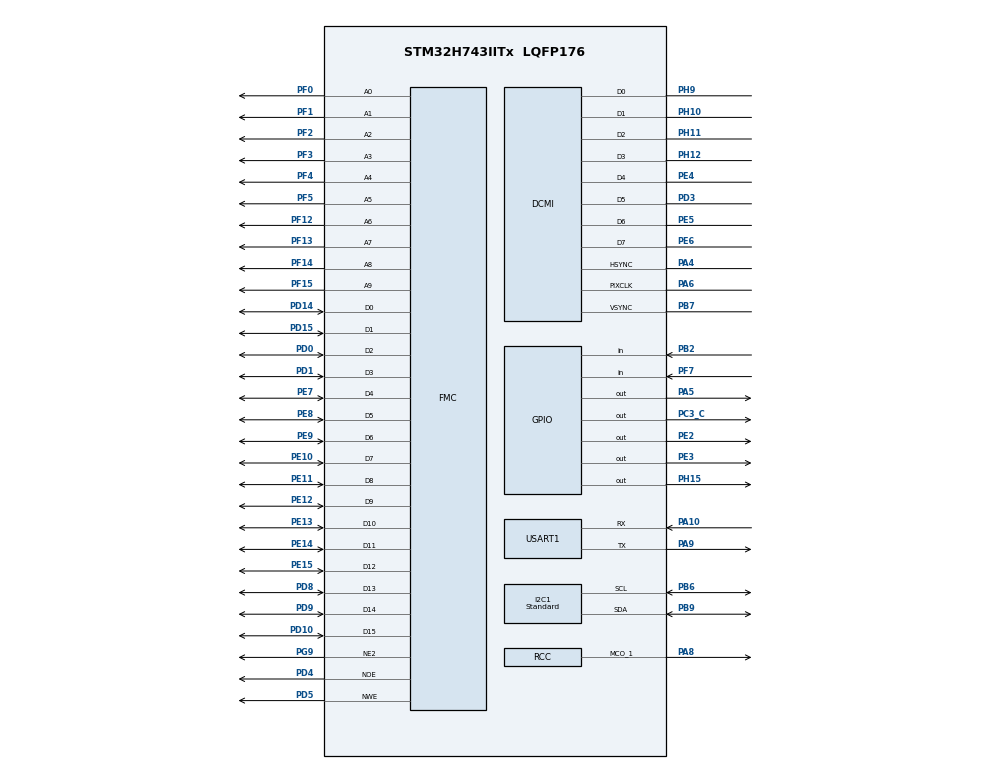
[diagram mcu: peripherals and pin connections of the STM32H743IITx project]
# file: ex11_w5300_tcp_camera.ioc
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DCMI.JPEGMode=DCMI_JPEG_DISABLE
DCMI.PCKPolarity=DCMI_PCKPOLARITY_RISING
Dma.DCMI.0.Direction=DMA_PERIPH_TO_MEMORY
Dma.DCMI.0.EventEnable=DISABLE
Dma.DCMI.0.FIFOMode=DMA_FIFOMODE_ENABLE
Dma.DCMI.0.FIFOThreshold=DMA_FIFO_THRESHOLD_FULL
Dma.DCMI.0.Instance=DMA2_Stream1
Dma.DCMI.0.MemBurst=DMA_MBURST_SINGLE
Dma.DCMI.0.MemDataAlignment=DMA_MDATAALIGN_WORD
Dma.DCMI.0.MemInc=DMA_MINC_ENABLE
Dma.DCMI.0.Mode=DMA_CIRCULAR
Dma.DCMI.0.PeriphBurst=DMA_PBURST_SINGLE
Dma.DCMI.0.PeriphDataAlignment=DMA_PDATAALIGN_WORD
Dma.DCMI.0.PeriphInc=DMA_PINC_DISABLE
Dma.DCMI.0.Polarity=HAL_DMAMUX_REQ_GEN_RISING
Dma.DCMI.0.Priority=DMA_PRIORITY_VERY_HIGH
Dma.DCMI.0.RequestNumber=1
Dma.DCMI.0.SignalID=NONE
Dma.DCMI.0.SyncEnable=DISABLE
Dma.DCMI.0.SyncPolarity=HAL_DMAMUX_SYNC_NO_EVENT
Dma.DCMI.0.SyncRequestNumber=1
Dma.DCMI.0.SyncSignalID=NONE
Dma.Request0=DCMI
FMC.ExtendedMode1=FMC_EXTENDED_MODE_ENABLE
FMC.WriteFifo1=FMC_WRITE_FIFO_DISABLE
FMC.WriteOperation1=FMC_WRITE_OPERATION_ENABLE
I2C1.I2C_Speed_Mode=I2C_Standard
I2C1.Timing=0x307075B1
Mcu.Family=STM32H7
Mcu.Name=STM32H743IITx
Mcu.Package=LQFP176
NVIC.DCMI_IRQn=true\:0\:0\:false\:false\:true\:true\:true\:true
NVIC.DMA2_Stream1_IRQn=true\:0\:0\:false\:false\:true\:false\:true\:true
NVIC.PriorityGroup=NVIC_PRIORITYGROUP_4
PA10.Mode=Asynchronous
PA10.Signal=USART1_RX
PA13\ (JTMS/SWDIO).Mode=Serial_Wire
PA13\ (JTMS/SWDIO).Signal=DEBUG_JTMS-SWDIO
PA14\ (JTCK/SWCLK).Mode=Serial_Wire
PA14\ (JTCK/SWCLK).Signal=DEBUG_JTCK-SWCLK
PA4.Mode=Slave_8_bits_External_Synchro
PA4.Signal=DCMI_HSYNC
PA5.Signal=GPIO_Output
PA6.Mode=Slave_8_bits_External_Synchro
PA6.Signal=DCMI_PIXCLK
PA8.Mode=Clock-out-1
PA8.Signal=RCC_MCO_1
PA9.Mode=Asynchronous
PA9.Signal=USART1_TX
PB10.Signal=I2C2_SCL
PB11.Signal=I2C2_SDA
PB2.Signal=GPIO_Input
PB6.Mode=I2C
PB6.Signal=I2C1_SCL
PB7.Mode=Slave_8_bits_External_Synchro
PB7.Signal=DCMI_VSYNC
PB9.Mode=I2C
PB9.Signal=I2C1_SDA
PC3_C.Signal=GPIO_Output
PD0.Signal=FMC_D2_DA2
PD1.Signal=FMC_D3_DA3
PD10.Signal=FMC_D15_DA15
PD14.Signal=FMC_D0_DA0
PD15.Signal=FMC_D1_DA1
PD3.Mode=Slave_8_bits_External_Synchro
PD3.Signal=DCMI_D5
PD4.Signal=FMC_NOE
PD5.Signal=FMC_NWE
PD7.Signal=FMC_NE1
PD8.Signal=FMC_D13_DA13
PD9.Signal=FMC_D14_DA14
PE10.Signal=FMC_D7_DA7
PE11.Signal=FMC_D8_DA8
PE12.Signal=FMC_D9_DA9
PE13.Signal=FMC_D10_DA10
PE14.Signal=FMC_D11_DA11
PE15.Signal=FMC_D12_DA12
PE2.Signal=GPIO_Output
PE3.Signal=GPIO_Output
PE4.Mode=Slave_8_bits_External_Synchro
PE4.Signal=DCMI_D4
PE5.Mode=Slave_8_bits_External_Synchro
PE5.Signal=DCMI_D6
PE6.Mode=Slave_8_bits_External_Synchro
PE6.Signal=DCMI_D7
PE7.Signal=FMC_D4_DA4
PE8.Signal=FMC_D5_DA5
PE9.Signal=FMC_D6_DA6
PF0.Signal=FMC_A0
PF1.Signal=FMC_A1
PF12.Signal=FMC_A6
PF13.Signal=FMC_A7
PF14.Signal=FMC_A8
PF15.Signal=FMC_A9
PF2.Signal=FMC_A2
PF3.Signal=FMC_A3
PF4.Signal=FMC_A4
PF5.Signal=FMC_A5
PF7.Signal=GPIO_Input
PG10.Signal=FMC_NE3
PG9.Mode=NorPsramChipSelect2_1
PG9.Signal=FMC_NE2
PH10.Mode=Slave_8_bits_External_Synchro
PH10.Signal=DCMI_D1
PH11.Mode=Slave_8_bits_External_Synchro
PH11.Signal=DCMI_D2
PH12.Mode=Slave_8_bits_External_Synchro
PH12.Signal=DCMI_D3
PH15.Signal=GPIO_Output
PH9.Mode=Slave_8_bits_External_Synchro
PH9.Signal=DCMI_D0
ProjectManager.HeapSize=0x200
ProjectManager.StackSize=0x400
ProjectManager.TargetToolchain=STM32CubeIDE
RCC.ADCFreq_Value=129000000
RCC.APB1Freq_Value=120000000
RCC.APB2Freq_Value=120000000
RCC.APB3Freq_Value=120000000
RCC.APB4Freq_Value=120000000
RCC.CortexFreq_Value=480000000
RCC.D1PPRE=RCC_APB3_DIV2
RCC.D2PPRE1=RCC_APB1_DIV2
RCC.D2PPRE2=RCC_APB2_DIV2
RCC.D3PPRE=RCC_APB4_DIV2
RCC.DIVM1=4
RCC.DIVN1=60
RCC.HCLKFreq_Value=240000000
RCC.HPRE=RCC_HCLK_DIV2
RCC.RCC_MCODiv1=RCC_MCODIV_4
RCC.SYSCLKFreq_VALUE=480000000
RCC.SYSCLKSource=RCC_SYSCLKSOURCE_PLLCLK
RCC.USBFreq_Value=480000000
SH.FMC_A0.0=FMC_A0,10b-a1
SH.FMC_A1.0=FMC_A1,10b-a1
SH.FMC_A2.0=FMC_A2,10b-a1
SH.FMC_A3.0=FMC_A3,10b-a1
SH.FMC_A4.0=FMC_A4,10b-a1
SH.FMC_A5.0=FMC_A5,10b-a1
SH.FMC_A6.0=FMC_A6,10b-a1
SH.FMC_A7.0=FMC_A7,10b-a1
SH.FMC_A8.0=FMC_A8,10b-a1
SH.FMC_A9.0=FMC_A9,10b-a1
SH.FMC_D0_DA0.0=FMC_D0,16b-d1
SH.FMC_D10_DA10.0=FMC_D10,16b-d1
SH.FMC_D11_DA11.0=FMC_D11,16b-d1
SH.FMC_D12_DA12.0=FMC_D12,16b-d1
SH.FMC_D13_DA13.0=FMC_D13,16b-d1
SH.FMC_D14_DA14.0=FMC_D14,16b-d1
SH.FMC_D15_DA15.0=FMC_D15,16b-d1
SH.FMC_D1_DA1.0=FMC_D1,16b-d1
SH.FMC_D2_DA2.0=FMC_D2,16b-d1
SH.FMC_D3_DA3.0=FMC_D3,16b-d1
SH.FMC_D4_DA4.0=FMC_D4,16b-d1
SH.FMC_D5_DA5.0=FMC_D5,16b-d1
SH.FMC_D6_DA6.0=FMC_D6,16b-d1
SH.FMC_D7_DA7.0=FMC_D7,16b-d1
SH.FMC_D8_DA8.0=FMC_D8,16b-d1
SH.FMC_D9_DA9.0=FMC_D9,16b-d1
SH.FMC_NOE.0=FMC_NOE,Sram1
SH.FMC_NWE.0=FMC_NWE,Sram1
USART1.VirtualMode-Asynchronous=VM_ASYNC
board=custom

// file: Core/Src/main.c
/* USER CODE BEGIN Header */
/**
  ******************************************************************************
  * @file           : main.c
  * @brief          : Main program body
  ******************************************************************************
  * @attention
  *
  * Copyright (c) 2023 STMicroelectronics.
  * All rights reserved.
  *
  * This software is licensed under terms that can be found in the LICENSE file
  * in the root directory of this software component.
  * If no LICENSE file comes with this software, it is provided AS-IS.
  *
  ******************************************************************************
  */
/* USER CODE END Header */
#include "main.h"

DCMI_HandleTypeDef hdcmi;
DMA_HandleTypeDef hdma_dcmi;

I2C_HandleTypeDef hi2c1;

UART_HandleTypeDef huart1;

SRAM_HandleTypeDef hsram1;

void SystemClock_Config(void);
static void MX_GPIO_Init(void);
static void MX_DMA_Init(void);
static void MX_DCMI_Init(void);
static void MX_FMC_Init(void);
static void MX_USART1_UART_Init(void);
static void MX_I2C1_Init(void);
/* USER CODE BEGIN PFP */

#define _CAM_SOCK_NUM		0
#define _CAM_ETHER_PORT		3000

#define _CMD_CAM_START		0xFE
#define _CMD_CAM_STOP		0xFD
#define _CMD_CAM_SIZE		0xFC
#define _CMD_LED			0xF0
#define _CMD_CAM_LINE		0xFB
#define _CMD_CAM_FRAME		0xFA

int gImgTransferFlag = 1;

unsigned int dDestport = _CAM_ETHER_PORT;

#include "wizchip_conf.h"
#include "_user_code_intit.h"
#include "_user_code_w5300.h"
#include "_user_code_cam.h"
/* USER CODE END PFP */

/* USER CODE BEGIN 0 */

void MPU_Config(void)
{
  /// Enable the MPU
  HAL_MPU_Enable(MPU_PRIVILEGED_DEFAULT);
  MPU_Region_InitTypeDef MPU_InitStruct;
  HAL_MPU_Disable();
  MPU_InitStruct.Enable=MPU_REGION_ENABLE;
  MPU_InitStruct.BaseAddress = 0x64000000;
  MPU_InitStruct.Size = MPU_REGION_SIZE_64KB;
  MPU_InitStruct.AccessPermission=MPU_REGION_FULL_ACCESS;
  MPU_InitStruct.TypeExtField=MPU_TEX_LEVEL0;
  MPU_InitStruct.IsCacheable=MPU_ACCESS_NOT_CACHEABLE;
  MPU_InitStruct.IsBufferable=MPU_ACCESS_BUFFERABLE;
  MPU_InitStruct.IsShareable=MPU_ACCESS_SHAREABLE;
  MPU_InitStruct.Number=MPU_REGION_NUMBER0;
  MPU_InitStruct.SubRegionDisable=0x00;
  MPU_InitStruct.DisableExec=MPU_INSTRUCTION_ACCESS_ENABLE;
  HAL_MPU_ConfigRegion(&MPU_InitStruct);
  HAL_MPU_Enable(MPU_PRIVILEGED_DEFAULT);
}

int32_t ProcessCamTcps(uint8_t sn, uint8_t* buf, uint16_t port)
{
   int32_t ret;
   uint16_t size = 0, sentsize=0;

	unsigned int cmd;
	unsigned int para;
#ifdef _LOOPBACK_DEBUG_
   uint8_t destip[4];
   uint16_t destport;
#endif

   switch(getSn_SR(sn))
   {
      case SOCK_ESTABLISHED :
         if(getSn_IR(sn) & Sn_IR_CON)
         {
#ifdef _LOOPBACK_DEBUG_
			getSn_DIPR(sn, destip);
			destport = getSn_DPORT(sn);

			printf("%d:Connected - %d.%d.%d.%d : %d\r\n",sn, destip[0], destip[1], destip[2], destip[3], destport);
#endif
			setSn_IR(sn,Sn_IR_CON);
         }
		 if((size = getSn_RX_RSR(sn)) > 0) // Don't need to check SOCKERR_BUSY because it doesn't not occur.
         {
			if(size > ETH_MAX_BUF_SIZE) size = ETH_MAX_BUF_SIZE;
			ret = recv(sn, buf, size);

			cmd = buf[0];
			para = buf[2]<<8 | buf[3];

            if(cmd == _CMD_LED)
            {
            	if(para == 0)
           		{
            		Led1Off();
           		}
            	else if(para == 1)
            	{
            		Led1On();
            	}
            }
            else if(cmd == _CMD_CAM_START)
            {
            	gImgTransferFlag = 1;
            	printf("Cam Stream Start\r\n");
            }
            else if(cmd == _CMD_CAM_STOP)
            {
            	gImgTransferFlag = 0;
            	printf("Cam Stream Stop\r\n");
            }

			//sendto(sock, data_buf, len, gDestip, dDestport);

			printf("rx size=%d	\r\n", size);
         }
         break;
      case SOCK_CLOSE_WAIT :
#ifdef _LOOPBACK_DEBUG_
         //printf("%d:CloseWait\r\n",sn);
#endif
         if((ret = disconnect(sn)) != SOCK_OK) return ret;
#ifdef _LOOPBACK_DEBUG_
         printf("%d:Socket Closed\r\n", sn);
#endif
         break;
      case SOCK_INIT :
#ifdef _LOOPBACK_DEBUG_
    	 printf("%d:Listen, TCP server loopback, port [%d]\r\n", sn, port);
#endif
         if( (ret = listen(sn)) != SOCK_OK) return ret;
         break;
      case SOCK_CLOSED:
#ifdef _LOOPBACK_DEBUG_
         //printf("%d:TCP server loopback start\r\n",sn);
#endif
         if((ret = socket(sn, Sn_MR_TCP, port, 0x00)) != sn) return ret;
#ifdef _LOOPBACK_DEBUG_
         //printf("%d:Socket opened\r\n",sn);
#endif

         break;
      default:
         break;
   }
   return 1;
}

void CamImagTransferLine(unsigned int Cmd, unsigned int Para)
{
  	int ret ;

	unsigned char data_buf[2048*_UDP_TX_BUF_RATE];
	unsigned int size = _IMAGE_SIZE_X*2*_UDP_TX_BUF_RATE;

  	data_buf[0] = Cmd;
  	data_buf[1] = 0;
  	data_buf[2] = Para>>8;
  	data_buf[3] = Para;

  	memcpy((uint8_t *)&data_buf[4], (uint8_t *)&FrameBuffer, size);

	if(gImgTransferFlag)
	{
		ret = send(_CAM_SOCK_NUM, (uint8_t *)data_buf, size+4);
	}
}

void CamImagTransferFrame(unsigned int Cmd, unsigned int Para)
{
	int ret ;
	unsigned char data_buf[2048*_UDP_TX_BUF_RATE];
	unsigned int size = _IMAGE_SIZE_X*2*_UDP_TX_BUF_RATE;

  	data_buf[0] = Cmd;
  	data_buf[1] = 0;
  	data_buf[2] = Para>>8;
  	data_buf[3] = Para;

	if(gImgTransferFlag)
	{
		HAL_Delay(1);
		ret = send(_CAM_SOCK_NUM, data_buf, size+4);
		HAL_Delay(1);
	}
}

/* USER CODE END 0 */

int main(void)
{
  /* USER CODE BEGIN 1 */
	unsigned int data;

	SCB_EnableICache();
	//SCB_EnableDCache();
	MPU_Config();

  /* USER CODE END 1 */

  /* MCU Configuration--------------------------------------------------------*/

  /* Reset of all peripherals, Initializes the Flash interface and the Systick. */
  HAL_Init();

  /* Configure the system clock */
  SystemClock_Config();

  /* Initialize all configured peripherals */
  MX_GPIO_Init();
  MX_DMA_Init();
  MX_DCMI_Init();
  MX_FMC_Init();
  MX_USART1_UART_Init();
  MX_I2C1_Init();
  /* USER CODE BEGIN 2 */
  printf("W5300 camera Test\r\n");

  _init_cam();
  _InitW5300();

	CameraStat();
  /* USER CODE END 2 */

  /* Infinite loop */
  while (1)
  {

    /* USER CODE BEGIN 3 */
		ProcessCamTcps(_CAM_SOCK_NUM, ethBuf0, dDestport);

	  	if(gCameraFrameFlag>0)
	  	{
	  		gCameraFrameFlag = 0;
	  		CamImagTransferFrame(_CMD_CAM_FRAME, gLineCnt);

	  		printf(">%d, %d\r\n", gFrameCnt, gLineCnt);
	  		printf("-------------------\r\n");
	  		gFrameCnt++;
	  		gLineCnt = 0;
	  	}

		if(gCameraLineFlag>0)
		{
			gCameraLineFlag = 0;

			CamImagTransferLine(_CMD_CAM_LINE, gLineCnt);
			//printf(">%d, %d\r\n", gFrameCnt, gLineCnt);
			gLineCnt++;
		}
  }
  /* USER CODE END 3 */
}

void SystemClock_Config(void)
{
  RCC_OscInitTypeDef RCC_OscInitStruct = {0};
  RCC_ClkInitTypeDef RCC_ClkInitStruct = {0};

  /** Supply configuration update enable
  */
  HAL_PWREx_ConfigSupply(PWR_LDO_SUPPLY);

  /** Configure the main internal regulator output voltage
  */
  __HAL_PWR_VOLTAGESCALING_CONFIG(PWR_REGULATOR_VOLTAGE_SCALE1);

  while(!__HAL_PWR_GET_FLAG(PWR_FLAG_VOSRDY)) {}

  __HAL_RCC_SYSCFG_CLK_ENABLE();
  __HAL_PWR_VOLTAGESCALING_CONFIG(PWR_REGULATOR_VOLTAGE_SCALE0);

  while(!__HAL_PWR_GET_FLAG(PWR_FLAG_VOSRDY)) {}

  /** Initializes the RCC Oscillators according to the specified parameters
  * in the RCC_OscInitTypeDef structure.
  */
  RCC_OscInitStruct.OscillatorType = RCC_OSCILLATORTYPE_HSI;
  RCC_OscInitStruct.HSIState = RCC_HSI_DIV1;
  RCC_OscInitStruct.HSICalibrationValue = RCC_HSICALIBRATION_DEFAULT;
  RCC_OscInitStruct.PLL.PLLState = RCC_PLL_ON;
  RCC_OscInitStruct.PLL.PLLSource = RCC_PLLSOURCE_HSI;
  RCC_OscInitStruct.PLL.PLLM = 4;
  RCC_OscInitStruct.PLL.PLLN = 60;
  RCC_OscInitStruct.PLL.PLLP = 2;
  RCC_OscInitStruct.PLL.PLLQ = 2;
  RCC_OscInitStruct.PLL.PLLR = 2;
  RCC_OscInitStruct.PLL.PLLRGE = RCC_PLL1VCIRANGE_3;
  RCC_OscInitStruct.PLL.PLLVCOSEL = RCC_PLL1VCOWIDE;
  RCC_OscInitStruct.PLL.PLLFRACN = 0;
  if (HAL_RCC_OscConfig(&RCC_OscInitStruct) != HAL_OK)
  {
    Error_Handler();
  }

  /** Initializes the CPU, AHB and APB buses clocks
  */
  RCC_ClkInitStruct.ClockType = RCC_CLOCKTYPE_HCLK|RCC_CLOCKTYPE_SYSCLK
                              |RCC_CLOCKTYPE_PCLK1|RCC_CLOCKTYPE_PCLK2
                              |RCC_CLOCKTYPE_D3PCLK1|RCC_CLOCKTYPE_D1PCLK1;
  RCC_ClkInitStruct.SYSCLKSource = RCC_SYSCLKSOURCE_PLLCLK;
  RCC_ClkInitStruct.SYSCLKDivider = RCC_SYSCLK_DIV1;
  RCC_ClkInitStruct.AHBCLKDivider = RCC_HCLK_DIV2;
  RCC_ClkInitStruct.APB3CLKDivider = RCC_APB3_DIV2;
  RCC_ClkInitStruct.APB1CLKDivider = RCC_APB1_DIV2;
  RCC_ClkInitStruct.APB2CLKDivider = RCC_APB2_DIV2;
  RCC_ClkInitStruct.APB4CLKDivider = RCC_APB4_DIV2;

  if (HAL_RCC_ClockConfig(&RCC_ClkInitStruct, FLASH_LATENCY_4) != HAL_OK)
  {
    Error_Handler();
  }
  HAL_RCC_MCOConfig(RCC_MCO1, RCC_MCO1SOURCE_HSI, RCC_MCODIV_6);
}

static void MX_DCMI_Init(void)
{

  hdcmi.Instance = DCMI;
  hdcmi.Init.SynchroMode = DCMI_SYNCHRO_HARDWARE;
  hdcmi.Init.PCKPolarity = DCMI_PCKPOLARITY_RISING;
  hdcmi.Init.VSPolarity = DCMI_VSPOLARITY_LOW;
  hdcmi.Init.HSPolarity = DCMI_HSPOLARITY_LOW;
  hdcmi.Init.CaptureRate = DCMI_CR_ALL_FRAME;
  hdcmi.Init.ExtendedDataMode = DCMI_EXTEND_DATA_8B;
  hdcmi.Init.JPEGMode = DCMI_JPEG_DISABLE;
  hdcmi.Init.ByteSelectMode = DCMI_BSM_ALL;
  hdcmi.Init.ByteSelectStart = DCMI_OEBS_ODD;
  hdcmi.Init.LineSelectMode = DCMI_LSM_ALL;
  hdcmi.Init.LineSelectStart = DCMI_OELS_ODD;
  if (HAL_DCMI_Init(&hdcmi) != HAL_OK)
  {
    Error_Handler();
  }
}

static void MX_I2C1_Init(void)
{

  hi2c1.Instance = I2C1;
  hi2c1.Init.Timing = 0x307075B1;
  hi2c1.Init.OwnAddress1 = 0;
  hi2c1.Init.AddressingMode = I2C_ADDRESSINGMODE_7BIT;
  hi2c1.Init.DualAddressMode = I2C_DUALADDRESS_DISABLE;
  hi2c1.Init.OwnAddress2 = 0;
  hi2c1.Init.OwnAddress2Masks = I2C_OA2_NOMASK;
  hi2c1.Init.GeneralCallMode = I2C_GENERALCALL_DISABLE;
  hi2c1.Init.NoStretchMode = I2C_NOSTRETCH_DISABLE;
  if (HAL_I2C_Init(&hi2c1) != HAL_OK)
  {
    Error_Handler();
  }

  /** Configure Analogue filter
  */
  if (HAL_I2CEx_ConfigAnalogFilter(&hi2c1, I2C_ANALOGFILTER_ENABLE) != HAL_OK)
  {
    Error_Handler();
  }

  /** Configure Digital filter
  */
  if (HAL_I2CEx_ConfigDigitalFilter(&hi2c1, 0) != HAL_OK)
  {
    Error_Handler();
  }

}

static void MX_USART1_UART_Init(void)
{

  huart1.Instance = USART1;
  huart1.Init.BaudRate = 115200;
  huart1.Init.WordLength = UART_WORDLENGTH_8B;
  huart1.Init.StopBits = UART_STOPBITS_1;
  huart1.Init.Parity = UART_PARITY_NONE;
  huart1.Init.Mode = UART_MODE_TX_RX;
  huart1.Init.HwFlowCtl = UART_HWCONTROL_NONE;
  huart1.Init.OverSampling = UART_OVERSAMPLING_16;
  huart1.Init.OneBitSampling = UART_ONE_BIT_SAMPLE_DISABLE;
  huart1.Init.ClockPrescaler = UART_PRESCALER_DIV1;
  huart1.AdvancedInit.AdvFeatureInit = UART_ADVFEATURE_NO_INIT;
  if (HAL_UART_Init(&huart1) != HAL_OK)
  {
    Error_Handler();
  }
  if (HAL_UARTEx_SetTxFifoThreshold(&huart1, UART_TXFIFO_THRESHOLD_1_8) != HAL_OK)
  {
    Error_Handler();
  }
  if (HAL_UARTEx_SetRxFifoThreshold(&huart1, UART_RXFIFO_THRESHOLD_1_8) != HAL_OK)
  {
    Error_Handler();
  }
  if (HAL_UARTEx_DisableFifoMode(&huart1) != HAL_OK)
  {
    Error_Handler();
  }

}

static void MX_DMA_Init(void)
{

  /* DMA controller clock enable */
  __HAL_RCC_DMA2_CLK_ENABLE();

  /* DMA interrupt init */
  /* DMA2_Stream1_IRQn interrupt configuration */
  HAL_NVIC_SetPriority(DMA2_Stream1_IRQn, 1, 0);
  HAL_NVIC_EnableIRQ(DMA2_Stream1_IRQn);

}

/* FMC initialization function */
static void MX_FMC_Init(void)
{
  FMC_NORSRAM_TimingTypeDef Timing = {0};
  FMC_NORSRAM_TimingTypeDef ExtTiming = {0};
  FMC_SDRAM_TimingTypeDef SdramTiming = {0};

  hsram1.Instance = FMC_NORSRAM_DEVICE;
  hsram1.Extended = FMC_NORSRAM_EXTENDED_DEVICE;
  /* hsram1.Init */
  hsram1.Init.NSBank              = FMC_NORSRAM_BANK2;
  hsram1.Init.DataAddressMux      = FMC_DATA_ADDRESS_MUX_DISABLE;
  hsram1.Init.MemoryType          = FMC_MEMORY_TYPE_SRAM;
  //hsram1.Init.MemoryType = FMC_MEMORY_TYPE_NOR;
  hsram1.Init.MemoryDataWidth     = FMC_NORSRAM_MEM_BUS_WIDTH_16;
  hsram1.Init.BurstAccessMode     = FMC_BURST_ACCESS_MODE_DISABLE;
  hsram1.Init.WaitSignalPolarity  = FMC_WAIT_SIGNAL_POLARITY_LOW;
  hsram1.Init.WaitSignalActive    = FMC_WAIT_TIMING_BEFORE_WS;
  hsram1.Init.WriteOperation      = FMC_WRITE_OPERATION_ENABLE;
  hsram1.Init.WaitSignal          = FMC_WAIT_SIGNAL_DISABLE;
  hsram1.Init.ExtendedMode        = FMC_EXTENDED_MODE_ENABLE;
  hsram1.Init.AsynchronousWait    = FMC_ASYNCHRONOUS_WAIT_DISABLE;
  hsram1.Init.WriteBurst          = FMC_WRITE_BURST_DISABLE;
  hsram1.Init.ContinuousClock     = FMC_CONTINUOUS_CLOCK_SYNC_ONLY;
  hsram1.Init.WriteFifo           = FMC_WRITE_FIFO_DISABLE;
  hsram1.Init.PageSize            = FMC_PAGE_SIZE_NONE;

  Timing.AddressSetupTime = 4;
  Timing.AddressHoldTime  = 4;
  Timing.DataSetupTime    = 10;
  Timing.BusTurnAroundDuration = 5;
  Timing.CLKDivision = 16;
  Timing.DataLatency = 17;
  Timing.AccessMode = FMC_ACCESS_MODE_A;

  ExtTiming.AddressSetupTime  = 4;
  ExtTiming.AddressHoldTime   = 4;
  ExtTiming.DataSetupTime     = 10;
  ExtTiming.BusTurnAroundDuration = 5;
  ExtTiming.CLKDivision = 16;
  ExtTiming.DataLatency = 17;
  ExtTiming.AccessMode = FMC_ACCESS_MODE_A;

  HAL_SRAM_Init(&hsram1, &Timing, &ExtTiming);

  /* USER CODE END FMC_Init 2 */
}

static void MX_GPIO_Init(void)
{
  GPIO_InitTypeDef GPIO_InitStruct = {0};

  /* GPIO Ports Clock Enable */
  __HAL_RCC_GPIOE_CLK_ENABLE();
  __HAL_RCC_GPIOF_CLK_ENABLE();
  __HAL_RCC_GPIOC_CLK_ENABLE();
  __HAL_RCC_GPIOA_CLK_ENABLE();
  __HAL_RCC_GPIOB_CLK_ENABLE();
  __HAL_RCC_GPIOH_CLK_ENABLE();
  __HAL_RCC_GPIOD_CLK_ENABLE();
  __HAL_RCC_GPIOG_CLK_ENABLE();

  /*Configure GPIO pin Output Level */
  HAL_GPIO_WritePin(GPIOE, GPIO_PIN_2|GPIO_PIN_3, GPIO_PIN_RESET);

  /*Configure GPIO pin Output Level */
  HAL_GPIO_WritePin(GPIOC, GPIO_PIN_3, GPIO_PIN_RESET);

  /*Configure GPIO pin Output Level */
  HAL_GPIO_WritePin(GPIOA, GPIO_PIN_5, GPIO_PIN_RESET);

  /*Configure GPIO pin Output Level */
  HAL_GPIO_WritePin(GPIOH, GPIO_PIN_15, GPIO_PIN_RESET);

  /*Configure GPIO pins : PE2 PE3 */
  GPIO_InitStruct.Pin = GPIO_PIN_2|GPIO_PIN_3;
  GPIO_InitStruct.Mode = GPIO_MODE_OUTPUT_PP;
  GPIO_InitStruct.Pull = GPIO_NOPULL;
  GPIO_InitStruct.Speed = GPIO_SPEED_FREQ_LOW;
  HAL_GPIO_Init(GPIOE, &GPIO_InitStruct);

  /*Configure GPIO pin : PF7 */
  GPIO_InitStruct.Pin = GPIO_PIN_7;
  GPIO_InitStruct.Mode = GPIO_MODE_INPUT;
  GPIO_InitStruct.Pull = GPIO_NOPULL;
  HAL_GPIO_Init(GPIOF, &GPIO_InitStruct);

  /*Configure GPIO pin : PC3 */
  GPIO_InitStruct.Pin = GPIO_PIN_3;
  GPIO_InitStruct.Mode = GPIO_MODE_OUTPUT_PP;
  GPIO_InitStruct.Pull = GPIO_NOPULL;
  GPIO_InitStruct.Speed = GPIO_SPEED_FREQ_LOW;
  HAL_GPIO_Init(GPIOC, &GPIO_InitStruct);

  /*Configure GPIO pin : PA5 */
  GPIO_InitStruct.Pin = GPIO_PIN_5;
  GPIO_InitStruct.Mode = GPIO_MODE_OUTPUT_PP;
  GPIO_InitStruct.Pull = GPIO_NOPULL;
  GPIO_InitStruct.Speed = GPIO_SPEED_FREQ_LOW;
  HAL_GPIO_Init(GPIOA, &GPIO_InitStruct);

  /*Configure GPIO pin : PB2 */
  GPIO_InitStruct.Pin = GPIO_PIN_2;
  GPIO_InitStruct.Mode = GPIO_MODE_INPUT;
  GPIO_InitStruct.Pull = GPIO_NOPULL;
  HAL_GPIO_Init(GPIOB, &GPIO_InitStruct);

  /*Configure GPIO pins : PB10 PB11 */
  GPIO_InitStruct.Pin = GPIO_PIN_10|GPIO_PIN_11;
  GPIO_InitStruct.Mode = GPIO_MODE_AF_OD;
  GPIO_InitStruct.Pull = GPIO_NOPULL;
  GPIO_InitStruct.Speed = GPIO_SPEED_FREQ_LOW;
  GPIO_InitStruct.Alternate = GPIO_AF4_I2C2;
  HAL_GPIO_Init(GPIOB, &GPIO_InitStruct);

  /*Configure GPIO pin : PA8 */
  GPIO_InitStruct.Pin = GPIO_PIN_8;
  GPIO_InitStruct.Mode = GPIO_MODE_AF_PP;
  GPIO_InitStruct.Pull = GPIO_NOPULL;
  GPIO_InitStruct.Speed = GPIO_SPEED_FREQ_LOW;
  GPIO_InitStruct.Alternate = GPIO_AF0_MCO;
  HAL_GPIO_Init(GPIOA, &GPIO_InitStruct);

  /*Configure GPIO pin : PH15 */
  GPIO_InitStruct.Pin = GPIO_PIN_15;
  GPIO_InitStruct.Mode = GPIO_MODE_OUTPUT_PP;
  GPIO_InitStruct.Pull = GPIO_NOPULL;
  GPIO_InitStruct.Speed = GPIO_SPEED_FREQ_LOW;
  HAL_GPIO_Init(GPIOH, &GPIO_InitStruct);

}

void Error_Handler(void)
{
  __disable_irq();
  while (1)
  {
  }
}
